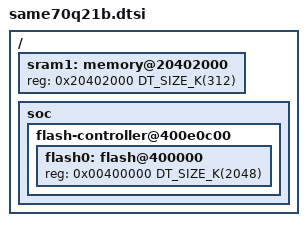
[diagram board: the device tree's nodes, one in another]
/*
 * Copyright (c) 2018 Linaro Limited
 * Copyright (c) 2020 Stephanos Ioannidis <root@stephanos.io>
 * Copyright (c) 2023 Gerson Fernando Budke <nandojve@gmail.com>
 *
 * SPDX-License-Identifier: Apache-2.0
 */

#include <mem.h>
#include <atmel/same70b.dtsi>
#include "dma_atmel_same70.h"

/ {
	sram1: memory@20402000 {
		reg = <0x20402000 DT_SIZE_K(312)>;
	};

	soc {
		flash-controller@400e0c00 {
			flash0: flash@400000 {
				reg = <0x00400000 DT_SIZE_K(2048)>;
			};
		};
	};
};
